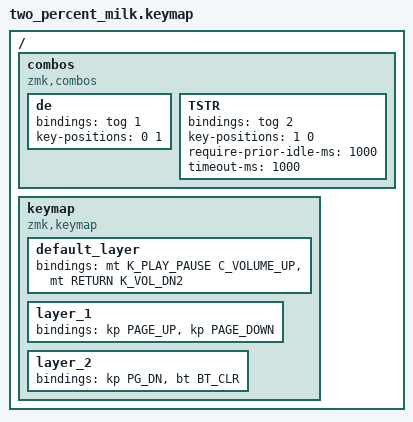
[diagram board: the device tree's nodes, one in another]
/*
 * Copyright (c) 2022 The ZMK Contributors
 *
 * SPDX-License-Identifier: MIT
 */

#include <behaviors.dtsi>
#include <dt-bindings/zmk/bt.h>
#include <dt-bindings/zmk/keys.h>

/ {
    combos {
        compatible = "zmk,combos";

        de {
            bindings = <&tog 1>;
            key-positions = <0 1>;
        };

        TSTR {
            bindings = <&tog 2>;
            key-positions = <1 0>;
            require-prior-idle-ms = <1000>;
            timeout-ms = <1000>;
        };
    };

    keymap {
        compatible = "zmk,keymap";

        default_layer {
            bindings = <
&mt K_PLAY_PAUSE C_VOLUME_UP  &mt RETURN K_VOL_DN2
            >;
        };

        layer_1 {
            bindings = <
&kp PAGE_UP  &kp PAGE_DOWN
            >;
        };

        layer_2 {
            bindings = <
&kp PG_DN  &bt BT_CLR
            >;
        };
    };
};
